# iostr750 register map
Registers are 16-bit, access not given, no defined reset value unless marked. A register's access mark holds for its fields unless they carry their own. Addresses are absolute; registers are grouped by the start of their names; [hi:lo] are bit positions; {n}, {i} and the like mark numbered series; 'fields as' and 'values as' point back to an identical list.

## PWM
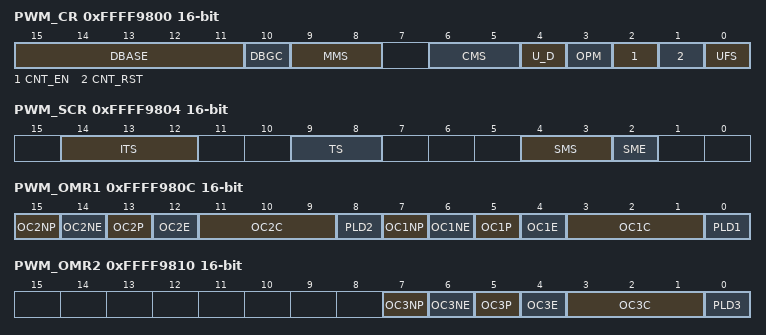
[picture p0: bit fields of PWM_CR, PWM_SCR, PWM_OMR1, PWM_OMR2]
0xFFFF9800 PWM_CR
  [15:11] DBASE, [10] DBGC, [9:8] MMS, [6:5] CMS, [4] U_D, [3] OPM, [2] CNT_EN, [1] CNT_RST, [0] UFS
0xFFFF9804 PWM_SCR
  [14:12] ITS, [9:8] TS, [4:3] SMS, [2] SME
0xFFFF980C PWM_OMR1
  [15] OC2NP, [14] OC2NE, [13] OC2P, [12] OC2E, [11:9] OC2C, [8] PLD2, [7] OC1NP, [6] OC1NE, [5] OC1P, [4] OC1E, [3:1] OC1C, [0] PLD1
0xFFFF9810 PWM_OMR2
  [7] OC3NP, [6] OC3NE, [5] OC3P, [4] OC3E, [3:1] OC3C, [0] PLD3
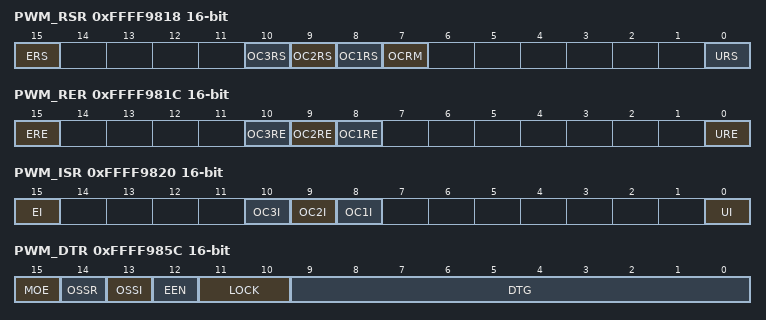
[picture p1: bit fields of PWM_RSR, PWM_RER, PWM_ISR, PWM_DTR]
0xFFFF9818 PWM_RSR
  [15] ERS, [10] OC3RS, [9] OC2RS, [8] OC1RS, [7] OCRM, [0] URS
0xFFFF981C PWM_RER
  [15] ERE, [10] OC3RE, [9] OC2RE, [8] OC1RE, [0] URE
0xFFFF9820 PWM_ISR
  [15] EI, [10] OC3I, [9] OC2I, [8] OC1I, [0] UI
0xFFFF9824 PWM_CNT
0xFFFF9828 PWM_PSC
0xFFFF982C PWM_RCR
  [7:0] REP
0xFFFF9830 PWM_ARR
{0xFFFF9830+4i} PWM_OCR{i} (i=1..3)
0xFFFF985C PWM_DTR
  [15] MOE, [14] OSSR, [13] OSSI, [12] EEN, [11:10] LOCK, [9:0] DTG
0xFFFF9860 PWM_DMAB

## CAN
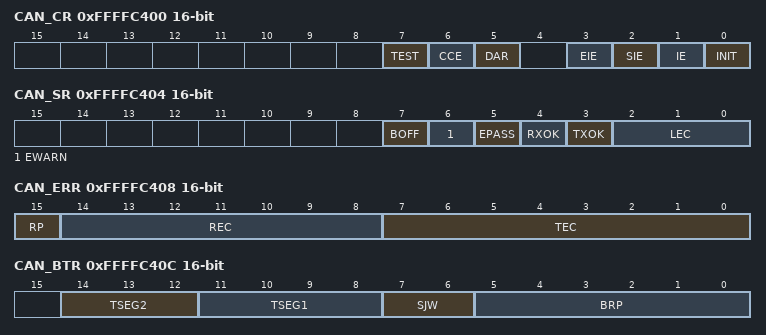
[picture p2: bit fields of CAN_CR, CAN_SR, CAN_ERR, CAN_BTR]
0xFFFFC400 CAN_CR
  [7] TEST, [6] CCE, [5] DAR, [3] EIE, [2] SIE, [1] IE, [0] INIT
0xFFFFC404 CAN_SR
  [7] BOFF, [6] EWARN, [5] EPASS, [4] RXOK, [3] TXOK, [2:0] LEC
0xFFFFC408 CAN_ERR
  [15] RP, [14:8] REC, [7:0] TEC
0xFFFFC40C CAN_BTR
  [14:12] TSEG2, [11:8] TSEG1, [7:6] SJW, [5:0] BRP
0xFFFFC410 CAN_IDR
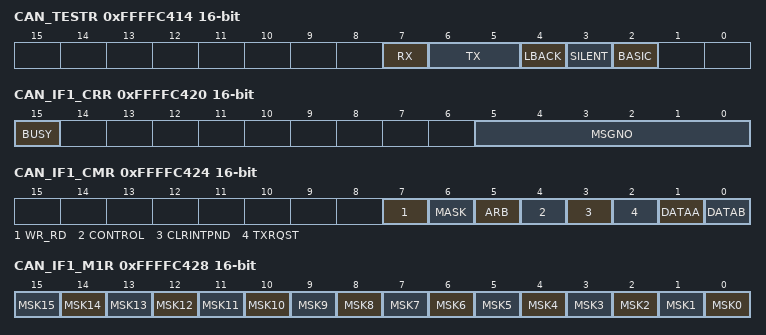
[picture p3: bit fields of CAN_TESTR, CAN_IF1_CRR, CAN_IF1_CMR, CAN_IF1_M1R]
0xFFFFC414 CAN_TESTR
  [7] RX, [6:5] TX, [4] LBACK, [3] SILENT, [2] BASIC
0xFFFFC418 CAN_BRPR
  [3:0] BRPE
0xFFFFC420 CAN_IF1_CRR
  [15] BUSY, [5:0] MSGNO
0xFFFFC424 CAN_IF1_CMR
  [7] WR_RD, [6] MASK, [5] ARB, [4] CONTROL, [3] CLRINTPND, [2] TXRQST, [1] DATAA, [0] DATAB
0xFFFFC428 CAN_IF1_M1R
  [n] MSK{n} (n=0..15)
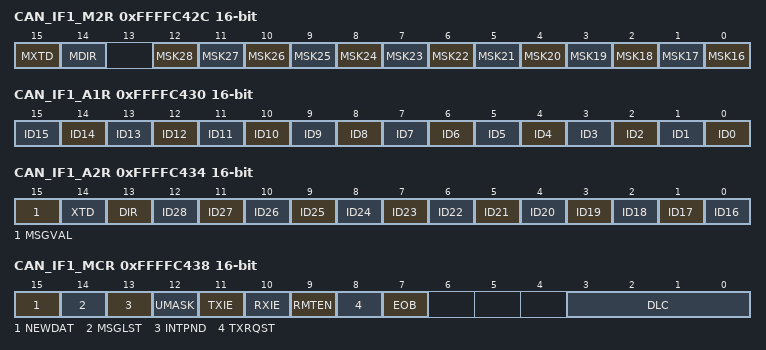
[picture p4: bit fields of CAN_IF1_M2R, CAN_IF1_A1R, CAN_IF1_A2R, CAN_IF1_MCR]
0xFFFFC42C CAN_IF1_M2R
  [15] MXTD, [14] MDIR, [n-16] MSK{n} (n=16..28)
0xFFFFC430 CAN_IF1_A1R
  [n] ID{n} (n=0..15)
0xFFFFC434 CAN_IF1_A2R
  [15] MSGVAL, [14] XTD, [13] DIR, [n-16] ID{n} (n=16..28)
0xFFFFC438 CAN_IF1_MCR
  [15] NEWDAT, [14] MSGLST, [13] INTPND, [12] UMASK, [11] TXIE, [10] RXIE, [9] RMTEN, [8] TXRQST, [7] EOB, [3:0] DLC
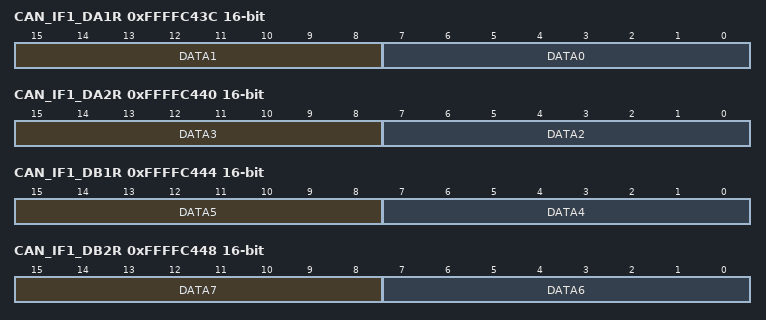
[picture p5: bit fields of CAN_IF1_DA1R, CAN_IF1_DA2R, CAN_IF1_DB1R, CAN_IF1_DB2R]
0xFFFFC43C CAN_IF1_DA1R
  [15:8] DATA1, [7:0] DATA0
0xFFFFC440 CAN_IF1_DA2R
  [15:8] DATA3, [7:0] DATA2
0xFFFFC444 CAN_IF1_DB1R
  [15:8] DATA5, [7:0] DATA4
0xFFFFC448 CAN_IF1_DB2R
  [15:8] DATA7, [7:0] DATA6
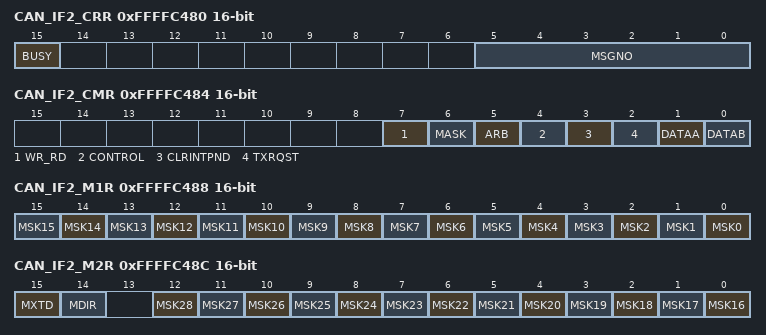
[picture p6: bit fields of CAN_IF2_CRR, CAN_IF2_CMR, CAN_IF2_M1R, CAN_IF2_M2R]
0xFFFFC480 CAN_IF2_CRR
  [15] BUSY, [5:0] MSGNO
0xFFFFC484 CAN_IF2_CMR
  fields as CAN_IF1_CMR
0xFFFFC488 CAN_IF2_M1R
  [n] MSK{n} (n=0..15)
0xFFFFC48C CAN_IF2_M2R
  [15] MXTD, [14] MDIR, [n-16] MSK{n} (n=16..28)
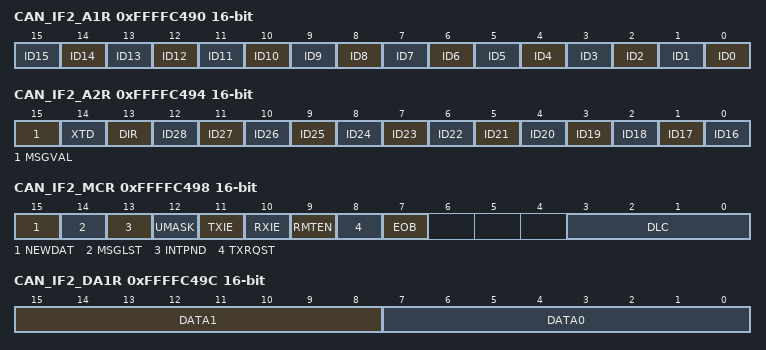
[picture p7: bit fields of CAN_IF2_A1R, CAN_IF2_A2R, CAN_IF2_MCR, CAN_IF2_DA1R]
0xFFFFC490 CAN_IF2_A1R
  [n] ID{n} (n=0..15)
0xFFFFC494 CAN_IF2_A2R
  [15] MSGVAL, [14] XTD, [13] DIR, [n-16] ID{n} (n=16..28)
0xFFFFC498 CAN_IF2_MCR
  fields as CAN_IF1_MCR
0xFFFFC49C CAN_IF2_DA1R
  [15:8] DATA1, [7:0] DATA0
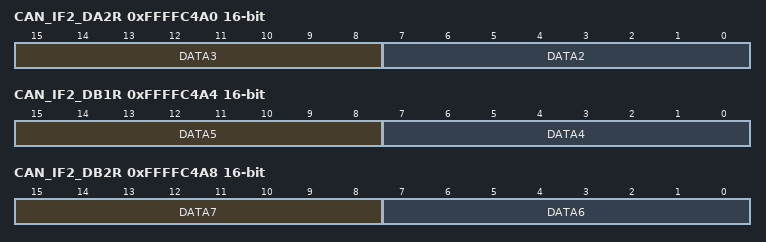
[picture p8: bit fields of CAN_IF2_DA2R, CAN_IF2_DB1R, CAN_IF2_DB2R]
0xFFFFC4A0 CAN_IF2_DA2R
  [15:8] DATA3, [7:0] DATA2
0xFFFFC4A4 CAN_IF2_DB1R
  [15:8] DATA5, [7:0] DATA4
0xFFFFC4A8 CAN_IF2_DB2R
  [15:8] DATA7, [7:0] DATA6
0xFFFFC500 CAN_TXR1R 32-bit
0xFFFFC504 CAN_TXR2R 32-bit
0xFFFFC520 CAN_ND1R 32-bit
0xFFFFC524 CAN_ND2R 32-bit
0xFFFFC540 CAN_IP1R 32-bit
0xFFFFC544 CAN_IP2R 32-bit
0xFFFFC560 CAN_MV1R 32-bit
0xFFFFC564 CAN_MV2R 32-bit

## I2C0
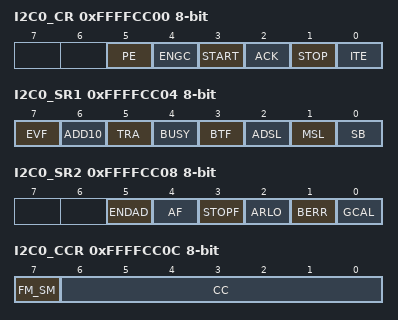
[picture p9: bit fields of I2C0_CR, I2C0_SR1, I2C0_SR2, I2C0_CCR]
0xFFFFCC00 I2C0_CR 8-bit
  [5] PE, [4] ENGC, [3] START, [2] ACK, [1] STOP, [0] ITE
0xFFFFCC04 I2C0_SR1 8-bit
  [7] EVF, [6] ADD10, [5] TRA, [4] BUSY, [3] BTF, [2] ADSL, [1] MSL, [0] SB
0xFFFFCC08 I2C0_SR2 8-bit
  [5] ENDAD, [4] AF, [3] STOPF, [2] ARLO, [1] BERR, [0] GCAL
0xFFFFCC0C I2C0_CCR 8-bit
  [7] FM_SM, [6:0] CC
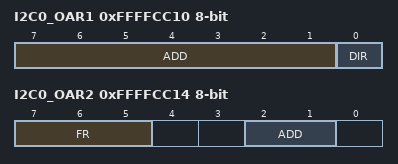
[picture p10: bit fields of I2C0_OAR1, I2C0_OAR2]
0xFFFFCC10 I2C0_OAR1 8-bit
  [7:1] ADD, [0] DIR
0xFFFFCC14 I2C0_OAR2 8-bit
  [7:5] FR, [2:1] ADD
0xFFFFCC18 I2C0_DR 8-bit
0xFFFFCC1C I2C0_ECCR 8-bit
  [4:0] CC

## SSP0
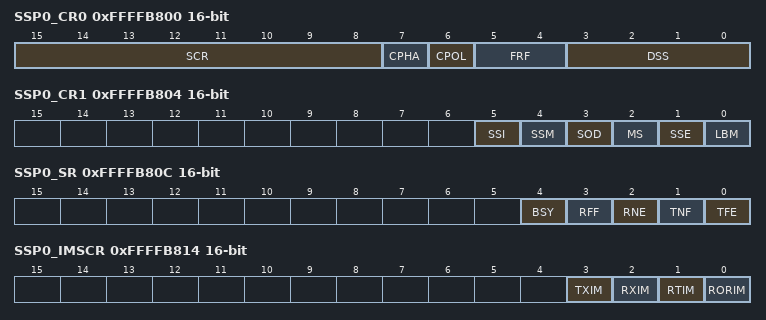
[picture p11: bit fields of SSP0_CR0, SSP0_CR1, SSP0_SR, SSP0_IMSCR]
0xFFFFB800 SSP0_CR0
  [15:8] SCR, [7] CPHA, [6] CPOL, [5:4] FRF, [3:0] DSS
0xFFFFB804 SSP0_CR1
  [5] SSI, [4] SSM, [3] SOD, [2] MS, [1] SSE, [0] LBM
0xFFFFB808 SSP0_DR
0xFFFFB80C SSP0_SR
  [4] BSY, [3] RFF, [2] RNE, [1] TNF, [0] TFE
0xFFFFB810 SSP0_PR
  [7:0] CPSDVSR
0xFFFFB814 SSP0_IMSCR
  [3] TXIM, [2] RXIM, [1] RTIM, [0] RORIM
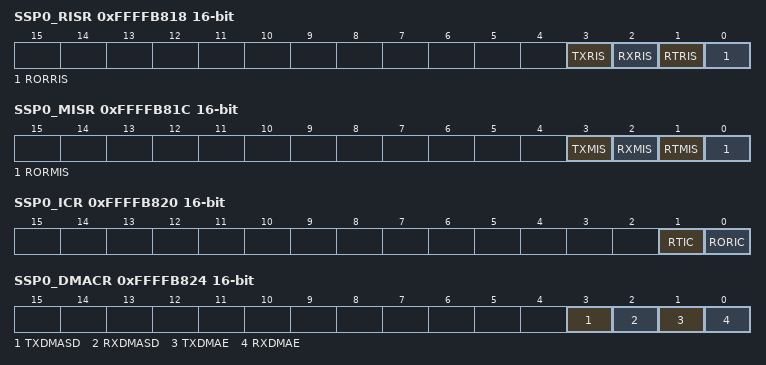
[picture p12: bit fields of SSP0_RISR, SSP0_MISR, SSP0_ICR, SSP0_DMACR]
0xFFFFB818 SSP0_RISR
  [3] TXRIS, [2] RXRIS, [1] RTRIS, [0] RORRIS
0xFFFFB81C SSP0_MISR
  [3] TXMIS, [2] RXMIS, [1] RTMIS, [0] RORMIS
0xFFFFB820 SSP0_ICR
  [1] RTIC, [0] RORIC
0xFFFFB824 SSP0_DMACR
  [3] TXDMASD, [2] RXDMASD, [1] TXDMAE, [0] RXDMAE
